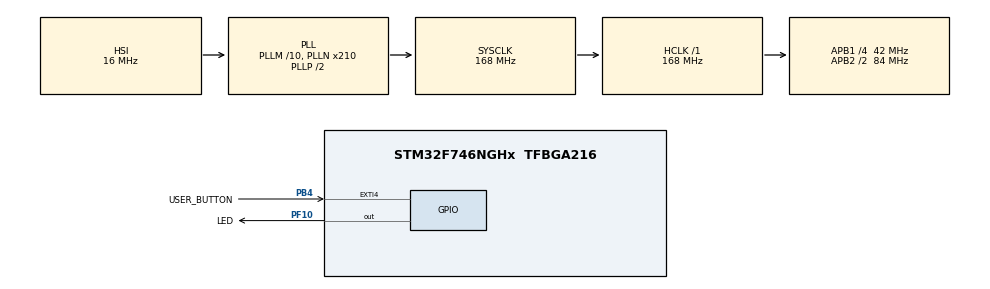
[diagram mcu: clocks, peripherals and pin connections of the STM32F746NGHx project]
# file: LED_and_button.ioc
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FREERTOS.Tasks01=defaultTask,0,128,StartDefaultTask,Default,NULL,Dynamic,NULL,NULL;StartLedBlinkin,-3,128,StartStartLedBlinking,Default,NULL,Dynamic,NULL,NULL;ButtonPushTask,-3,128,StartButtonPushTask,Default,NULL,Dynamic,NULL,NULL
Mcu.Family=STM32F7
Mcu.Name=STM32F746NGHx
Mcu.Package=TFBGA216
NVIC.EXTI4_IRQn=true\:6\:0\:true\:false\:true\:false\:true\:true
NVIC.PriorityGroup=NVIC_PRIORITYGROUP_4
NVIC.TIM8_TRG_COM_TIM14_IRQn=true\:0\:0\:false\:false\:true\:false\:false\:true
NVIC.TimeBase=TIM8_TRG_COM_TIM14_IRQn
NVIC.TimeBaseIP=TIM14
PA13.Mode=Serial_Wire
PA13.Signal=SYS_JTMS-SWDIO
PA14.Mode=Serial_Wire
PA14.Signal=SYS_JTCK-SWCLK
PB4.GPIO_Label=USER_BUTTON
PB4.GPIO_ModeDefaultEXTI=GPIO_MODE_IT_RISING_FALLING
PB4.GPIO_PuPd=GPIO_PULLDOWN
PB4.Signal=GPXTI4
PC14/OSC32_IN.Mode=LSE-External-Clock-Source
PC14/OSC32_IN.Signal=RCC_OSC32_IN
PC15/OSC32_OUT.Mode=LSE-External-Clock-Source
PC15/OSC32_OUT.Signal=RCC_OSC32_OUT
PF10.GPIO_Label=LED
PF10.Signal=GPIO_Output
PH0/OSC_IN.Mode=HSE-External-Oscillator
PH0/OSC_IN.Signal=RCC_OSC_IN
PH1/OSC_OUT.Mode=HSE-External-Oscillator
PH1/OSC_OUT.Signal=RCC_OSC_OUT
ProjectManager.HeapSize=0x200
ProjectManager.StackSize=0x400
ProjectManager.TargetToolchain=STM32CubeIDE
RCC.AHBFreq_Value=168000000
RCC.APB1CLKDivider=RCC_HCLK_DIV4
RCC.APB1Freq_Value=42000000
RCC.APB1TimFreq_Value=84000000
RCC.APB2CLKDivider=RCC_HCLK_DIV2
RCC.APB2Freq_Value=84000000
RCC.APB2TimFreq_Value=168000000
RCC.CortexFreq_Value=168000000
RCC.HCLKFreq_Value=168000000
RCC.HSE_VALUE=25000000
RCC.HSI_VALUE=16000000
RCC.LSE_VALUE=32768
RCC.PLLM=10
RCC.PLLN=210
RCC.PLLSourceVirtual=RCC_PLLSOURCE_HSI
RCC.SYSCLKFreq_VALUE=168000000
RCC.SYSCLKSource=RCC_SYSCLKSOURCE_PLLCLK
RCC.USBFreq_Value=168000000
RCC.VCOOutputFreq_Value=336000000
VP_FREERTOS_VS_CMSIS_V1.Mode=CMSIS_V1
VP_SYS_VS_tim14.Mode=TIM14
board=STM32F746G-DISCO

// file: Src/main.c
/* USER CODE BEGIN Header */
/**
  ******************************************************************************
  * @file           : main.c
  * @brief          : Main program body
  ******************************************************************************
  * @attention
  *
  * <h2><center>&copy; Copyright (c) 2019 STMicroelectronics.
  * All rights reserved.</center></h2>
  *
  * This software component is licensed by ST under BSD 3-Clause license,
  * the "License"; You may not use this file except in compliance with the
  * License. You may obtain a copy of the License at:
  *                        opensource.org/licenses/BSD-3-Clause
  *
  ******************************************************************************
  */
/* USER CODE END Header */

#include "main.h"
#include "cmsis_os.h"

/* USER CODE BEGIN Includes */
#include "stdio.h"
/* USER CODE END Includes */

/* USER CODE BEGIN PTD */
typedef enum blinking_state{
	BUTTON_PRESSED,
	BUTTON_NOT_PRESSED
}blinking_state_t;
/* USER CODE END PTD */

osThreadId defaultTaskHandle;
osThreadId StartLedBlinkinHandle;
osThreadId ButtonPushTaskHandle;
/* USER CODE BEGIN PV */
int counter = 0;
int prev_start_time = 0;
int prev_rel_time = 0;
blinking_state_t blinking;
/* USER CODE END PV */

void SystemClock_Config(void);
static void MX_GPIO_Init(void);
void StartDefaultTask(void const * argument);
void StartStartLedBlinking(void const * argument);
void StartButtonPushTask(void const * argument);

int main(void)
{

  /* MCU Configuration--------------------------------------------------------*/

  /* Reset of all peripherals, Initializes the Flash interface and the Systick. */
  HAL_Init();

  /* Configure the system clock */
  SystemClock_Config();

  /* Initialize all configured peripherals */
  MX_GPIO_Init();

  /* Create the thread(s) */
  /* definition and creation of defaultTask */
  osThreadDef(defaultTask, StartDefaultTask, osPriorityNormal, 0, 128);
  defaultTaskHandle = osThreadCreate(osThread(defaultTask), NULL);

  /* definition and creation of StartLedBlinkin */
  osThreadDef(StartLedBlinkin, StartStartLedBlinking, osPriorityIdle, 0, 128);
  StartLedBlinkinHandle = osThreadCreate(osThread(StartLedBlinkin), NULL);

  /* definition and creation of ButtonPushTask */
  osThreadDef(ButtonPushTask, StartButtonPushTask, osPriorityIdle, 0, 128);
  ButtonPushTaskHandle = osThreadCreate(osThread(ButtonPushTask), NULL);

  /* Start scheduler */
  osKernelStart();

  /* We should never get here as control is now taken by the scheduler */

  /* Infinite loop */
  while (1)
  {

  }
}

void SystemClock_Config(void)
{
  RCC_OscInitTypeDef RCC_OscInitStruct = {0};
  RCC_ClkInitTypeDef RCC_ClkInitStruct = {0};

  /** Configure the main internal regulator output voltage
  */
  __HAL_RCC_PWR_CLK_ENABLE();
  __HAL_PWR_VOLTAGESCALING_CONFIG(PWR_REGULATOR_VOLTAGE_SCALE2);
  /** Initializes the CPU, AHB and APB busses clocks
  */
  RCC_OscInitStruct.OscillatorType = RCC_OSCILLATORTYPE_HSI;
  RCC_OscInitStruct.HSIState = RCC_HSI_ON;
  RCC_OscInitStruct.HSICalibrationValue = RCC_HSICALIBRATION_DEFAULT;
  RCC_OscInitStruct.PLL.PLLState = RCC_PLL_ON;
  RCC_OscInitStruct.PLL.PLLSource = RCC_PLLSOURCE_HSI;
  RCC_OscInitStruct.PLL.PLLM = 10;
  RCC_OscInitStruct.PLL.PLLN = 210;
  RCC_OscInitStruct.PLL.PLLP = RCC_PLLP_DIV2;
  RCC_OscInitStruct.PLL.PLLQ = 2;
  if (HAL_RCC_OscConfig(&RCC_OscInitStruct) != HAL_OK)
  {
    Error_Handler();
  }
  /** Initializes the CPU, AHB and APB busses clocks
  */
  RCC_ClkInitStruct.ClockType = RCC_CLOCKTYPE_HCLK|RCC_CLOCKTYPE_SYSCLK
                              |RCC_CLOCKTYPE_PCLK1|RCC_CLOCKTYPE_PCLK2;
  RCC_ClkInitStruct.SYSCLKSource = RCC_SYSCLKSOURCE_PLLCLK;
  RCC_ClkInitStruct.AHBCLKDivider = RCC_SYSCLK_DIV1;
  RCC_ClkInitStruct.APB1CLKDivider = RCC_HCLK_DIV4;
  RCC_ClkInitStruct.APB2CLKDivider = RCC_HCLK_DIV2;

  if (HAL_RCC_ClockConfig(&RCC_ClkInitStruct, FLASH_LATENCY_5) != HAL_OK)
  {
    Error_Handler();
  }
}

static void MX_GPIO_Init(void)
{
  GPIO_InitTypeDef GPIO_InitStruct = {0};

  /* GPIO Ports Clock Enable */
  __HAL_RCC_GPIOB_CLK_ENABLE();
  __HAL_RCC_GPIOA_CLK_ENABLE();
  __HAL_RCC_GPIOC_CLK_ENABLE();
  __HAL_RCC_GPIOH_CLK_ENABLE();
  __HAL_RCC_GPIOF_CLK_ENABLE();

  /*Configure GPIO pin Output Level */
  HAL_GPIO_WritePin(LED_GPIO_Port, LED_Pin, GPIO_PIN_RESET);

  /*Configure GPIO pin : USER_BUTTON_Pin */
  GPIO_InitStruct.Pin = USER_BUTTON_Pin;
  GPIO_InitStruct.Mode = GPIO_MODE_IT_RISING_FALLING;
  GPIO_InitStruct.Pull = GPIO_PULLDOWN;
  HAL_GPIO_Init(USER_BUTTON_GPIO_Port, &GPIO_InitStruct);

  /*Configure GPIO pin : LED_Pin */
  GPIO_InitStruct.Pin = LED_Pin;
  GPIO_InitStruct.Mode = GPIO_MODE_OUTPUT_PP;
  GPIO_InitStruct.Pull = GPIO_NOPULL;
  GPIO_InitStruct.Speed = GPIO_SPEED_FREQ_LOW;
  HAL_GPIO_Init(LED_GPIO_Port, &GPIO_InitStruct);

  /* EXTI interrupt init*/
  HAL_NVIC_SetPriority(EXTI4_IRQn, 6, 0);
  HAL_NVIC_EnableIRQ(EXTI4_IRQn);

}

/* USER CODE BEGIN 4 */
void HAL_GPIO_EXTI_Callback(uint16_t GPIO_Pin){
	if(GPIO_Pin == USER_BUTTON_Pin){
		if(HAL_GetTick() - 300 < prev_start_time){
		return;
		}
		counter++;
	if(HAL_GPIO_ReadPin(USER_BUTTON_GPIO_Port, USER_BUTTON_Pin) == 1){
		prev_start_time = HAL_GetTick();
	}
	 if(HAL_GPIO_ReadPin(USER_BUTTON_GPIO_Port, USER_BUTTON_Pin) == 0 ){
	   prev_rel_time = HAL_GetTick();

	 if(prev_start_time + 2000 < prev_rel_time){
		 osSignalSet(StartLedBlinkinHandle, 1);
	 }
   }
 }
}
/* USER CODE END 4 */

void StartDefaultTask(void const * argument)
{

  for(;;)
  {
    osDelay(1);
  }
}

void StartStartLedBlinking(void const * argument)
{
  /* USER CODE BEGIN StartStartLedBlinking */
  /* Infinite loop */
  for(;;)
  {
	  osSignalWait(1, osWaitForever);
	  for(int i = 0; i < 50 ; i++){
		  HAL_GPIO_TogglePin(LED_GPIO_Port, LED_Pin);
		  osDelay(100);
	  }

  }
  /* USER CODE END StartStartLedBlinking */
}

void StartButtonPushTask(void const * argument)
{
  for(;;)
  {
  }
}

void HAL_TIM_PeriodElapsedCallback(TIM_HandleTypeDef *htim)
{
  if (htim->Instance == TIM14) {
    HAL_IncTick();
  }
}

void Error_Handler(void)
{
}

/************************ (C) COPYRIGHT STMicroelectronics *****END OF FILE****/
